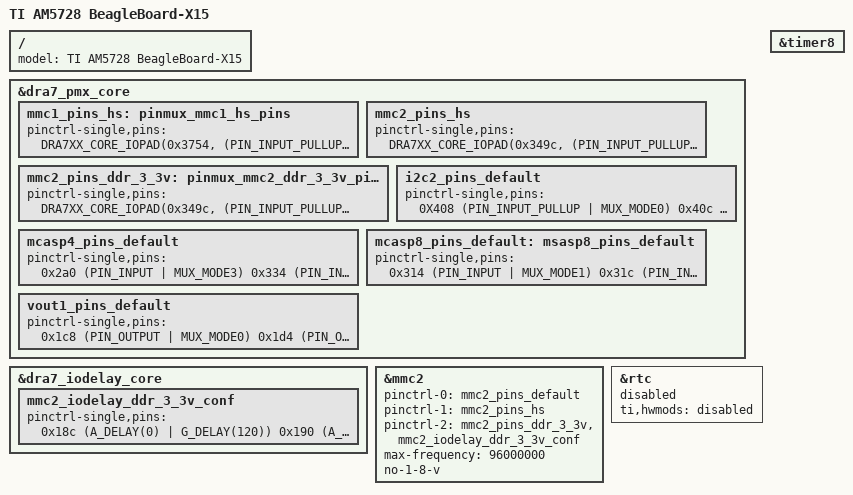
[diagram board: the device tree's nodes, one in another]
/*
 * Copyright (C) 2014-2016 Texas Instruments Incorporated - http://www.ti.com/
 *
 * This program is free software; you can redistribute it and/or modify
 * it under the terms of the GNU General Public License version 2 as
 * published by the Free Software Foundation.
 */
#include "am57xx-beagle-x15-reg.dtsi"
#include "am57xx-commercial-grade.dtsi"

/ {
        model = "TI AM5728 BeagleBoard-X15";
};

&dra7_pmx_core {

        mmc1_pins_hs: pinmux_mmc1_hs_pins {
                pinctrl-single,pins = <
                        DRA7XX_CORE_IOPAD(0x3754, (PIN_INPUT_PULLUP | MUX_VIRTUAL_MODE11 | MUX_MODE0)) /* mmc1_clk.clk */
                        DRA7XX_CORE_IOPAD(0x3758, (PIN_INPUT_PULLUP | MUX_VIRTUAL_MODE11 | MUX_MODE0)) /* mmc1_cmd.cmd */
                        DRA7XX_CORE_IOPAD(0x375c, (PIN_INPUT_PULLUP | MUX_VIRTUAL_MODE11 | MUX_MODE0)) /* mmc1_dat0.dat0 */
                        DRA7XX_CORE_IOPAD(0x3760, (PIN_INPUT_PULLUP | MUX_VIRTUAL_MODE11 | MUX_MODE0)) /* mmc1_dat1.dat1 */
                        DRA7XX_CORE_IOPAD(0x3764, (PIN_INPUT_PULLUP | MUX_VIRTUAL_MODE11 | MUX_MODE0)) /* mmc1_dat2.dat2 */
                        DRA7XX_CORE_IOPAD(0x3768, (PIN_INPUT_PULLUP | MUX_VIRTUAL_MODE11 | MUX_MODE0)) /* mmc1_dat3.dat3 */
                >;
        };

        mmc2_pins_hs: mmc2_pins_hs {
                pinctrl-single,pins = <
                        DRA7XX_CORE_IOPAD(0x349c, (PIN_INPUT_PULLUP | MUX_MODE1)) /* gpmc_a23.mmc2_clk */
                        DRA7XX_CORE_IOPAD(0x34b0, (PIN_INPUT_PULLUP | MUX_MODE1)) /* gpmc_cs1.mmc2_cmd */
                        DRA7XX_CORE_IOPAD(0x34a0, (PIN_INPUT_PULLUP | MUX_MODE1)) /* gpmc_a24.mmc2_dat0 */
                        DRA7XX_CORE_IOPAD(0x34a4, (PIN_INPUT_PULLUP | MUX_MODE1)) /* gpmc_a25.mmc2_dat1 */
                        DRA7XX_CORE_IOPAD(0x34a8, (PIN_INPUT_PULLUP | MUX_MODE1)) /* gpmc_a26.mmc2_dat2 */
                        DRA7XX_CORE_IOPAD(0x34ac, (PIN_INPUT_PULLUP | MUX_MODE1)) /* gpmc_a27.mmc2_dat3 */
                        DRA7XX_CORE_IOPAD(0x348c, (PIN_INPUT_PULLUP | MUX_MODE1)) /* gpmc_a19.mmc2_dat4 */
                        DRA7XX_CORE_IOPAD(0x3490, (PIN_INPUT_PULLUP | MUX_MODE1)) /* gpmc_a20.mmc2_dat5 */
                        DRA7XX_CORE_IOPAD(0x3494, (PIN_INPUT_PULLUP | MUX_MODE1)) /* gpmc_a21.mmc2_dat6 */
                        DRA7XX_CORE_IOPAD(0x3498, (PIN_INPUT_PULLUP | MUX_MODE1)) /* gpmc_a22.mmc2_dat7 */
                >;
        };

        mmc2_pins_ddr_3_3v: pinmux_mmc2_ddr_3_3v_pins {
                pinctrl-single,pins = <
                        DRA7XX_CORE_IOPAD(0x349c, (PIN_INPUT_PULLUP | MANUAL_MODE | MUX_MODE1)) /* gpmc_a23.mmc2_clk */
                        DRA7XX_CORE_IOPAD(0x34b0, (PIN_INPUT_PULLUP | MANUAL_MODE | MUX_MODE1)) /* gpmc_cs1.mmc2_cmd */
                        DRA7XX_CORE_IOPAD(0x34a0, (PIN_INPUT_PULLUP | MANUAL_MODE | MUX_MODE1)) /* gpmc_a24.mmc2_dat0 */
                        DRA7XX_CORE_IOPAD(0x34a4, (PIN_INPUT_PULLUP | MANUAL_MODE | MUX_MODE1)) /* gpmc_a25.mmc2_dat1 */
                        DRA7XX_CORE_IOPAD(0x34a8, (PIN_INPUT_PULLUP | MANUAL_MODE | MUX_MODE1)) /* gpmc_a26.mmc2_dat2 */
                        DRA7XX_CORE_IOPAD(0x34ac, (PIN_INPUT_PULLUP | MANUAL_MODE | MUX_MODE1)) /* gpmc_a27.mmc2_dat3 */
                        DRA7XX_CORE_IOPAD(0x348c, (PIN_INPUT_PULLUP | MANUAL_MODE | MUX_MODE1)) /* gpmc_a19.mmc2_dat4 */
                        DRA7XX_CORE_IOPAD(0x3490, (PIN_INPUT_PULLUP | MANUAL_MODE | MUX_MODE1)) /* gpmc_a20.mmc2_dat5 */
                        DRA7XX_CORE_IOPAD(0x3494, (PIN_INPUT_PULLUP | MANUAL_MODE | MUX_MODE1)) /* gpmc_a21.mmc2_dat6 */
                        DRA7XX_CORE_IOPAD(0x3498, (PIN_INPUT_PULLUP | MANUAL_MODE | MUX_MODE1)) /* gpmc_a22.mmc2_dat7 */
                >;
        };

	/* i2c2 */
	i2c2_pins_default: i2c2_pins_default {
		pinctrl-single,pins = <
			0X408 (PIN_INPUT_PULLUP | MUX_MODE0) /* Set i2c2_sda to i2c2_sda (ball C25) */
			0x40c (PIN_INPUT_PULLUP | MUX_MODE0) /* Set i2c2_scl to i2c2_scl (ball F17) */
		>;
	};

	/* McASP pins  */

	/* Left tlv320adc3101 */
	mcasp4_pins_default: mcasp4_pins_default {
		pinctrl-single,pins = <
			/*0x2a0 (PIN_OUTPUT | MUX_MODE9) * Set mcasp4_ahclkx to xref_clk3 (ball C23) */
			0x2a0 (PIN_INPUT | MUX_MODE3) /* Set mcasp4_ahclkx to xref_clk3 (ball C23) */
			/*0x334 (PIN_OUTPUT | MUX_MODE0) * Set mcasp4_aclkx to mcasp4_aclkr (ball C18 ) */
			/*0X338 (PIN_OUTPUT | MUX_MODE1) * Set mcasp4_fsx to msasp4_fsr (ball A21) */
			0x334 (PIN_INPUT | MUX_MODE1) /* Set mcasp4_aclkx to mcasp4_aclkr (ball C18 ) */
			0X338 (PIN_INPUT | MUX_MODE1) /* Set mcasp4_fsx to msasp4_fsr (ball A21) */
			0x33c (PIN_INPUT | MUX_MODE0) /* Set mcasp4_axr0 to mcasp_axr0 (ball G16) */
		>;
	};

	/* Right tlv320adc3101 */
	mcasp8_pins_default: msasp8_pins_default{
		pinctrl-single,pins = <
		/*	0x2a0 (PIN_OUTPUT | MUX_MODE4)  Set mcasp8_hclk to xref_clk3 (ball C23) */
			0x314 (PIN_INPUT | MUX_MODE1) /* Set mcasp2_axr4 to mcasp8_axr0 (ball D15) */
			0x31c (PIN_INPUT | MUX_MODE2) /* Set mcasp2_axr6 to mcasp8_aclkr (ball B17 ) */
			0x320 (PIN_INPUT | MUX_MODE2) /* Set mcasp2_axr7 to mcasp8_fsr (ball A17) */
		>;
	};


/* Display subsystem pins  */

	/* vout1 */
	vout1_pins_default: vout1_pins_default {
		pinctrl-single,pins = <
			0x1c8 (PIN_OUTPUT | MUX_MODE0) /* Set vout1_clk to vout1_clk (ball D11) */
			0x1d4 (PIN_OUTPUT | MUX_MODE0) /* Set vout1_hsync to vout1_hsync (ball C11) */	
			0x1d8 (PIN_OUTPUT | MUX_MODE0) /* Set vout1_vsync to vout1_vsync (ball E11) */ 
			0x1e4 (PIN_OUTPUT | MUX_MODE0) /* Set vout1_d2 to vout1_d2 (ball F10) */
			0x1e8 (PIN_OUTPUT | MUX_MODE0) /* Set vout1_d3 to vout1_d3 (ball G11) */
			0x1eC (PIN_OUTPUT | MUX_MODE0) /* Set vout1_d4 to vout1_d4 (ball E9) */
			0x1f0 (PIN_OUTPUT | MUX_MODE0) /* Set vout1_d5 to vout1_d5 (ball F9) */
			0x1f4 (PIN_OUTPUT | MUX_MODE0) /* Set vout1_d6 to vout1_d6 (ball F8) */
			0x1f8 (PIN_OUTPUT | MUX_MODE0) /* Set vout1_d7 to vout1_d7 (ball E7) */
			0x1fc (PIN_OUTPUT | MUX_MODE0) /* Set vout1_d8 to vout1_d8 (ball E8) */
			0x200 (PIN_OUTPUT | MUX_MODE0) /* Set vout1_d9 to vout1_d9 (ball D9) */
		>;
	};

};

&dra7_iodelay_core {
        mmc2_iodelay_ddr_3_3v_conf: mmc2_iodelay_ddr_3_3v_conf {
                pinctrl-single,pins = <
                        0x18c (A_DELAY(0) | G_DELAY(120))	/* CFG_GPMC_A19_IN */
                        0x190 (A_DELAY(0) | G_DELAY(0))		/* CFG_GPMC_A19_OEN */
                        0x194 (A_DELAY(174) | G_DELAY(0))	/* CFG_GPMC_A19_OUT */
                        0x1a4 (A_DELAY(265) | G_DELAY(360))	/* CFG_GPMC_A20_IN */
                        0x1a8 (A_DELAY(0) | G_DELAY(0))		/* CFG_GPMC_A20_OEN */
                        0x1ac (A_DELAY(168) | G_DELAY(0))	/* CFG_GPMC_A20_OUT */
                        0x1b0 (A_DELAY(0) | G_DELAY(120))	/* CFG_GPMC_A21_IN */
                        0x1b4 (A_DELAY(0) | G_DELAY(0))		/* CFG_GPMC_A21_OEN */
                        0x1b8 (A_DELAY(136) | G_DELAY(0))	/* CFG_GPMC_A21_OUT */
                        0x1bc (A_DELAY(0) | G_DELAY(120))	/* CFG_GPMC_A22_IN */
                        0x1c0 (A_DELAY(0) | G_DELAY(0))		/* CFG_GPMC_A22_OEN */
                        0x1c4 (A_DELAY(0) | G_DELAY(0))		/* CFG_GPMC_A22_OUT */
                        0x1c8 (A_DELAY(287) | G_DELAY(420))	/* CFG_GPMC_A23_IN */
                        0x1d0 (A_DELAY(879) | G_DELAY(0))	/* CFG_GPMC_A23_OUT */
                        0x1d4 (A_DELAY(144) | G_DELAY(240))	/* CFG_GPMC_A24_IN */
                        0x1d8 (A_DELAY(0) | G_DELAY(0))		/* CFG_GPMC_A24_OEN */
                        0x1dc (A_DELAY(0) | G_DELAY(0))		/* CFG_GPMC_A24_OUT */
                        0x1e0 (A_DELAY(0) | G_DELAY(0))		/* CFG_GPMC_A25_IN */
                        0x1e4 (A_DELAY(0) | G_DELAY(0))		/* CFG_GPMC_A25_OEN */
                        0x1e8 (A_DELAY(34) | G_DELAY(0))	/* CFG_GPMC_A25_OUT */
                        0x1ec (A_DELAY(0) | G_DELAY(120))	/* CFG_GPMC_A26_IN */
                        0x1f0 (A_DELAY(0) | G_DELAY(0))		/* CFG_GPMC_A26_OEN */
                        0x1f4 (A_DELAY(120) | G_DELAY(0))	/* CFG_GPMC_A26_OUT */
                        0x1f8 (A_DELAY(120) | G_DELAY(180))	/* CFG_GPMC_A27_IN */
                        0x1fc (A_DELAY(0) | G_DELAY(0))		/* CFG_GPMC_A27_OEN */
                        0x200 (A_DELAY(0) | G_DELAY(0))		/* CFG_GPMC_A27_OUT */
                        0x360 (A_DELAY(0) | G_DELAY(0))		/* CFG_GPMC_CS1_IN */
                        0x364 (A_DELAY(0) | G_DELAY(0))		/* CFG_GPMC_CS1_OEN */
                        0x368 (A_DELAY(11) | G_DELAY(0))	/* CFG_GPMC_CS1_OUT */
                >;
        };
};
/*
&tpd12s015 {
        gpios = <&gpio7 10 GPIO_ACTIVE_HIGH>,	* gpio7_10, CT CP HPD *
                <&gpio6 28 GPIO_ACTIVE_HIGH>,	* gpio6_28, LS OE *
                <&gpio7 12 GPIO_ACTIVE_HIGH>;	* gpio7_12/sp1_cs2, HPD *
};
*/
&mmc2 {
        pinctrl-names = "default", "hs", "ddr_1_8v";
        pinctrl-0 = <&mmc2_pins_default>;
        pinctrl-1 = <&mmc2_pins_hs>;
        pinctrl-2 = <&mmc2_pins_ddr_3_3v &mmc2_iodelay_ddr_3_3v_conf>;

        max-frequency = <96000000>;
        no-1-8-v;
        /delete-property/ mmc-hs200-1_8v;
};


&rtc {
    status = "disabled";
    ti,hwmods = "disabled";
};

/*
&rtc {
    status = "okay";
};
*/

&timer8 {
    status = "okay";
};

#include "am57xx-evm-cmem.dtsi"
